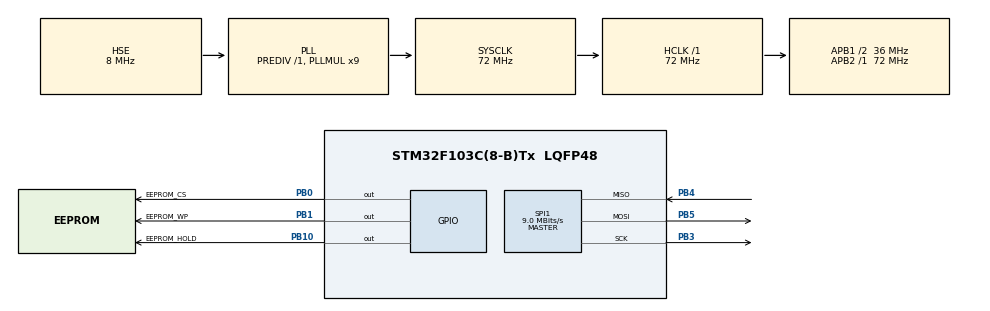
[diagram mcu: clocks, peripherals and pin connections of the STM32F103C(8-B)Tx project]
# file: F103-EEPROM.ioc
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FREERTOS.INCLUDE_xTaskAbortDelay=0
FREERTOS.INCLUDE_xTaskGetHandle=0
FREERTOS.MEMORY_ALLOCATION=0
FREERTOS.Tasks01=defaultTask,0,128,StartDefaultTask,Default,NULL
FREERTOS.configUSE_DAEMON_TASK_STARTUP_HOOK=0
Mcu.Family=STM32F1
Mcu.Name=STM32F103C(8-B)Tx
Mcu.Package=LQFP48
NVIC.PriorityGroup=NVIC_PRIORITYGROUP_4
NVIC.TIM2_IRQn=true\:0\:0\:false\:false\:true\:false\:true
NVIC.TimeBase=TIM2_IRQn
NVIC.TimeBaseIP=TIM2
PA13.Mode=Serial_Wire
PA13.Signal=SYS_JTMS-SWDIO
PA14.Mode=Serial_Wire
PA14.Signal=SYS_JTCK-SWCLK
PB0.GPIO_Label=EEPROM_CS
PB0.GPIO_Speed=GPIO_SPEED_FREQ_HIGH
PB0.PinState=GPIO_PIN_SET
PB0.Signal=GPIO_Output
PB1.GPIO_Label=EEPROM_WP
PB1.GPIO_Speed=GPIO_SPEED_FREQ_LOW
PB1.PinState=GPIO_PIN_SET
PB1.Signal=GPIO_Output
PB10.GPIO_Label=EEPROM_HOLD
PB10.PinState=GPIO_PIN_SET
PB10.Signal=GPIO_Output
PB3.Mode=Full_Duplex_Master
PB3.Signal=SPI1_SCK
PB4.Mode=Full_Duplex_Master
PB4.Signal=SPI1_MISO
PB5.Mode=Full_Duplex_Master
PB5.Signal=SPI1_MOSI
PC14-OSC32_IN.Mode=LSE-External-Oscillator
PC14-OSC32_IN.Signal=RCC_OSC32_IN
PC15-OSC32_OUT.Mode=LSE-External-Oscillator
PC15-OSC32_OUT.Signal=RCC_OSC32_OUT
PD0-OSC_IN.Mode=HSE-External-Oscillator
PD0-OSC_IN.Signal=RCC_OSC_IN
PD1-OSC_OUT.Mode=HSE-External-Oscillator
PD1-OSC_OUT.Signal=RCC_OSC_OUT
ProjectManager.HeapSize=0x200
ProjectManager.StackSize=0x400
ProjectManager.TargetToolchain=TrueSTUDIO
RCC.AHBFreq_Value=72000000
RCC.APB1CLKDivider=RCC_HCLK_DIV2
RCC.APB1Freq_Value=36000000
RCC.APB1TimFreq_Value=72000000
RCC.APB2Freq_Value=72000000
RCC.APB2TimFreq_Value=72000000
RCC.HCLKFreq_Value=72000000
RCC.PLLMUL=RCC_PLL_MUL9
RCC.PLLSourceVirtual=RCC_PLLSOURCE_HSE
RCC.RTCClockSelection=RCC_RTCCLKSOURCE_LSE
RCC.SYSCLKFreq_VALUE=72000000
RCC.SYSCLKSource=RCC_SYSCLKSOURCE_PLLCLK
RCC.USBFreq_Value=72000000
SPI1.BaudRatePrescaler=SPI_BAUDRATEPRESCALER_8
SPI1.CalculateBaudRate=9.0 MBits/s
SPI1.Direction=SPI_DIRECTION_2LINES
SPI1.Mode=SPI_MODE_MASTER
SPI1.VirtualType=VM_MASTER
VP_FREERTOS_VS_ENABLE.Mode=Enabled
VP_IWDG_VS_IWDG.Mode=IWDG_Activate
VP_RTC_VS_RTC_Activate.Mode=RTC_Enabled
VP_RTC_VS_RTC_Calendar.Mode=RTC_Calendar
VP_SYS_VS_tim2.Mode=TIM2
board=F103-EEPROM

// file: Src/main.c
/* USER CODE BEGIN Header */
/**
  ******************************************************************************
  * @file           : main.c
  * @brief          : Main program body
  ******************************************************************************
  * This notice applies to any and all portions of this file
  * that are not between comment pairs USER CODE BEGIN and
  * USER CODE END. Other portions of this file, whether
  * inserted by the user or by software development tools
  * are owned by their respective copyright owners.
  *
  * Copyright (c) 2019 STMicroelectronics International N.V.
  * All rights reserved.
  *
  * Redistribution and use in source and binary forms, with or without
  * modification, are permitted, provided that the following conditions are met:
  *
  * 1. Redistribution of source code must retain the above copyright notice,
  *    this list of conditions and the following disclaimer.
  * 2. Redistributions in binary form must reproduce the above copyright notice,
  *    this list of conditions and the following disclaimer in the documentation
  *    and/or other materials provided with the distribution.
  * 3. Neither the name of STMicroelectronics nor the names of other
  *    contributors to this software may be used to endorse or promote products
  *    derived from this software without specific written permission.
  * 4. This software, including modifications and/or derivative works of this
  *    software, must execute solely and exclusively on microcontroller or
  *    microprocessor devices manufactured by or for STMicroelectronics.
  * 5. Redistribution and use of this software other than as permitted under
  *    this license is void and will automatically terminate your rights under
  *    this license.
  *
  * THIS SOFTWARE IS PROVIDED BY STMICROELECTRONICS AND CONTRIBUTORS "AS IS"
  * AND ANY EXPRESS, IMPLIED OR STATUTORY WARRANTIES, INCLUDING, BUT NOT
  * LIMITED TO, THE IMPLIED WARRANTIES OF MERCHANTABILITY, FITNESS FOR A
  * PARTICULAR PURPOSE AND NON-INFRINGEMENT OF THIRD PARTY INTELLECTUAL PROPERTY
  * RIGHTS ARE DISCLAIMED TO THE FULLEST EXTENT PERMITTED BY LAW. IN NO EVENT
  * SHALL STMICROELECTRONICS OR CONTRIBUTORS BE LIABLE FOR ANY DIRECT, INDIRECT,
  * INCIDENTAL, SPECIAL, EXEMPLARY, OR CONSEQUENTIAL DAMAGES (INCLUDING, BUT NOT
  * LIMITED TO, PROCUREMENT OF SUBSTITUTE GOODS OR SERVICES; LOSS OF USE, DATA,
  * OR PROFITS; OR BUSINESS INTERRUPTION) HOWEVER CAUSED AND ON ANY THEORY OF
  * LIABILITY, WHETHER IN CONTRACT, STRICT LIABILITY, OR TORT (INCLUDING
  * NEGLIGENCE OR OTHERWISE) ARISING IN ANY WAY OUT OF THE USE OF THIS SOFTWARE,
  * EVEN IF ADVISED OF THE POSSIBILITY OF SUCH DAMAGE.
  *
  ******************************************************************************
  */
/* USER CODE END Header */

#include "main.h"
#include "cmsis_os.h"

/* USER CODE BEGIN Includes */
#include "STM32_EEPROM_SPI.h"
/* USER CODE END Includes */

IWDG_HandleTypeDef hiwdg;

RTC_HandleTypeDef hrtc;

SPI_HandleTypeDef hspi1;

osThreadId defaultTaskHandle;
/* USER CODE BEGIN PV */
extern uint8_t RxBuffer[32];
extern uint8_t EEPROM_StatusByte;

uint8_t TxBuffer[32] = "TEST THIS COOL EEPROM STM SPI ++";

/* USER CODE END PV */

void SystemClock_Config(void);
static void MX_GPIO_Init(void);
static void MX_IWDG_Init(void);
static void MX_RTC_Init(void);
static void MX_SPI1_Init(void);
void StartDefaultTask(void const * argument);

/* USER CODE BEGIN PFP */
/* Private function prototypes -----------------------------------------------*/

/* USER CODE END PFP */

int main(void) {

    /* MCU Configuration--------------------------------------------------------*/

    /* Reset of all peripherals, Initializes the Flash interface and the Systick. */
    HAL_Init();

    /* Configure the system clock */
    SystemClock_Config();

    /* Initialize all configured peripherals */
    MX_GPIO_Init();
    MX_IWDG_Init();
    MX_RTC_Init();
    MX_SPI1_Init();

    /* Create the thread(s) */
    /* definition and creation of defaultTask */
    osThreadDef(defaultTask, StartDefaultTask, osPriorityNormal, 0, 128);
    defaultTaskHandle = osThreadCreate(osThread(defaultTask), NULL);

    /* Start scheduler */
    osKernelStart();

    /* We should never get here as control is now taken by the scheduler */

    /* Infinite loop */
    while (1) {

    }
}

void SystemClock_Config(void) {
    RCC_OscInitTypeDef RCC_OscInitStruct = {0};
    RCC_ClkInitTypeDef RCC_ClkInitStruct = {0};
    RCC_PeriphCLKInitTypeDef PeriphClkInit = {0};

    /**Initializes the CPU, AHB and APB busses clocks
    */
    RCC_OscInitStruct.OscillatorType = RCC_OSCILLATORTYPE_LSI | RCC_OSCILLATORTYPE_HSE
                                       | RCC_OSCILLATORTYPE_LSE;
    RCC_OscInitStruct.HSEState = RCC_HSE_ON;
    RCC_OscInitStruct.HSEPredivValue = RCC_HSE_PREDIV_DIV1;
    RCC_OscInitStruct.LSEState = RCC_LSE_ON;
    RCC_OscInitStruct.HSIState = RCC_HSI_ON;
    RCC_OscInitStruct.LSIState = RCC_LSI_ON;
    RCC_OscInitStruct.PLL.PLLState = RCC_PLL_ON;
    RCC_OscInitStruct.PLL.PLLSource = RCC_PLLSOURCE_HSE;
    RCC_OscInitStruct.PLL.PLLMUL = RCC_PLL_MUL9;

    if (HAL_RCC_OscConfig(&RCC_OscInitStruct) != HAL_OK) {
        Error_Handler();
    }

    /**Initializes the CPU, AHB and APB busses clocks
    */
    RCC_ClkInitStruct.ClockType = RCC_CLOCKTYPE_HCLK | RCC_CLOCKTYPE_SYSCLK
                                  | RCC_CLOCKTYPE_PCLK1 | RCC_CLOCKTYPE_PCLK2;
    RCC_ClkInitStruct.SYSCLKSource = RCC_SYSCLKSOURCE_PLLCLK;
    RCC_ClkInitStruct.AHBCLKDivider = RCC_SYSCLK_DIV1;
    RCC_ClkInitStruct.APB1CLKDivider = RCC_HCLK_DIV2;
    RCC_ClkInitStruct.APB2CLKDivider = RCC_HCLK_DIV1;

    if (HAL_RCC_ClockConfig(&RCC_ClkInitStruct, FLASH_LATENCY_2) != HAL_OK) {
        Error_Handler();
    }

    PeriphClkInit.PeriphClockSelection = RCC_PERIPHCLK_RTC;
    PeriphClkInit.RTCClockSelection = RCC_RTCCLKSOURCE_LSE;

    if (HAL_RCCEx_PeriphCLKConfig(&PeriphClkInit) != HAL_OK) {
        Error_Handler();
    }
}

static void MX_IWDG_Init(void) {

    hiwdg.Instance = IWDG;
    hiwdg.Init.Prescaler = IWDG_PRESCALER_4;
    hiwdg.Init.Reload = 4095;

    if (HAL_IWDG_Init(&hiwdg) != HAL_OK) {
        Error_Handler();
    }

}

static void MX_RTC_Init(void) {

    RTC_TimeTypeDef sTime = {0};
    RTC_DateTypeDef DateToUpdate = {0};

    /**Initialize RTC Only
    */
    hrtc.Instance = RTC;
    hrtc.Init.AsynchPrediv = RTC_AUTO_1_SECOND;
    hrtc.Init.OutPut = RTC_OUTPUTSOURCE_ALARM;

    if (HAL_RTC_Init(&hrtc) != HAL_OK) {
        Error_Handler();
    }

    /**Initialize RTC and set the Time and Date
    */
    sTime.Hours = 0x0;
    sTime.Minutes = 0x0;
    sTime.Seconds = 0x0;

    if (HAL_RTC_SetTime(&hrtc, &sTime, RTC_FORMAT_BCD) != HAL_OK) {
        Error_Handler();
    }

    DateToUpdate.WeekDay = RTC_WEEKDAY_MONDAY;
    DateToUpdate.Month = RTC_MONTH_JANUARY;
    DateToUpdate.Date = 0x1;
    DateToUpdate.Year = 0x0;

    if (HAL_RTC_SetDate(&hrtc, &DateToUpdate, RTC_FORMAT_BCD) != HAL_OK) {
        Error_Handler();
    }

}

static void MX_SPI1_Init(void) {

    /* SPI1 parameter configuration*/
    hspi1.Instance = SPI1;
    hspi1.Init.Mode = SPI_MODE_MASTER;
    hspi1.Init.Direction = SPI_DIRECTION_2LINES;
    hspi1.Init.DataSize = SPI_DATASIZE_8BIT;
    hspi1.Init.CLKPolarity = SPI_POLARITY_LOW;
    hspi1.Init.CLKPhase = SPI_PHASE_1EDGE;
    hspi1.Init.NSS = SPI_NSS_SOFT;
    hspi1.Init.BaudRatePrescaler = SPI_BAUDRATEPRESCALER_8;
    hspi1.Init.FirstBit = SPI_FIRSTBIT_MSB;
    hspi1.Init.TIMode = SPI_TIMODE_DISABLE;
    hspi1.Init.CRCCalculation = SPI_CRCCALCULATION_DISABLE;
    hspi1.Init.CRCPolynomial = 10;

    if (HAL_SPI_Init(&hspi1) != HAL_OK) {
        Error_Handler();
    }

}

static void MX_GPIO_Init(void) {
    GPIO_InitTypeDef GPIO_InitStruct = {0};

    /* GPIO Ports Clock Enable */
    __HAL_RCC_GPIOC_CLK_ENABLE();
    __HAL_RCC_GPIOD_CLK_ENABLE();
    __HAL_RCC_GPIOB_CLK_ENABLE();
    __HAL_RCC_GPIOA_CLK_ENABLE();

    /*Configure GPIO pin Output Level */
    HAL_GPIO_WritePin(GPIOB, EEPROM_CS_Pin | EEPROM_WP_Pin | EEPROM_HOLD_Pin, GPIO_PIN_SET);

    /*Configure GPIO pin : EEPROM_CS_Pin */
    GPIO_InitStruct.Pin = EEPROM_CS_Pin;
    GPIO_InitStruct.Mode = GPIO_MODE_OUTPUT_PP;
    GPIO_InitStruct.Pull = GPIO_NOPULL;
    GPIO_InitStruct.Speed = GPIO_SPEED_FREQ_HIGH;
    HAL_GPIO_Init(EEPROM_CS_GPIO_Port, &GPIO_InitStruct);

    /*Configure GPIO pins : EEPROM_WP_Pin EEPROM_HOLD_Pin */
    GPIO_InitStruct.Pin = EEPROM_WP_Pin | EEPROM_HOLD_Pin;
    GPIO_InitStruct.Mode = GPIO_MODE_OUTPUT_PP;
    GPIO_InitStruct.Pull = GPIO_NOPULL;
    GPIO_InitStruct.Speed = GPIO_SPEED_FREQ_LOW;
    HAL_GPIO_Init(GPIOB, &GPIO_InitStruct);

}

void StartDefaultTask(void const * argument) {

    /* USER CODE BEGIN 5 */
    /* Infinite loop */
    EEPROM_SPI_INIT(&hspi1);

    EEPROM_SPI_WriteBuffer(TxBuffer, (uint16_t)0x01, (uint16_t)32);

    for (;;) {
        EEPROM_SPI_ReadBuffer(RxBuffer, (uint16_t)0x01, (uint16_t)32);

        osDelay(5000);
    }

    /* USER CODE END 5 */
}

void HAL_TIM_PeriodElapsedCallback(TIM_HandleTypeDef *htim) {
    if (htim->Instance == TIM2) {
        HAL_IncTick();
    }

}

void Error_Handler(void) {
}

/************************ (C) COPYRIGHT STMicroelectronics *****END OF FILE****/
